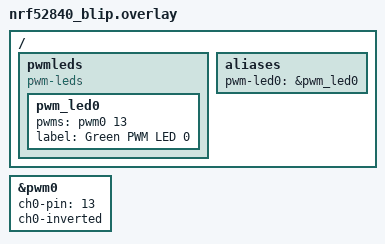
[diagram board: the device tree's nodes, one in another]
 / {
 	pwmleds {
 		compatible = "pwm-leds";
 		pwm_led0: pwm_led0 {
 			pwms = <&pwm0 13>;
 			label = "Green PWM LED 0";
		};
	};

	aliases {
		pwm-led0 = &pwm_led0;
	};
};

&pwm0 {
	status = "okay";
	ch0-pin = <13>;
	ch0-inverted;
};
